# bao1x_peri register map
Vendor: baochip
Registers are 32-bit, read-write, reset 0x0 unless marked. A register's access mark holds for its fields unless they carry their own. Offsets are from the block's base; [hi:lo] are bit positions; {n}, {i} and the like mark numbered series; <NAME> marks a mode.

## PWM
Base 0x50120000
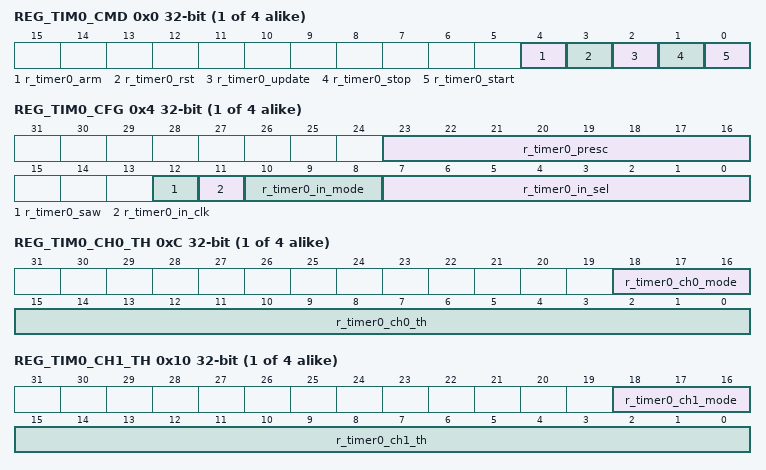
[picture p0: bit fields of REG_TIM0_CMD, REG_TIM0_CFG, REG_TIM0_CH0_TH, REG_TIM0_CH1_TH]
{0x0+0x40*i} REG_TIM{i}_CMD (i=0..3) — See `adv_timer_apb_if.sv <https://github.com/baochip/baochip-1x/blob/main/rtl/ip s/apb/apb_adv_timer/rtl/adv_timer_apb_if.sv>`__
  [4] r_timer{i}_arm, [3] r_timer{i}_rst, [2] r_timer{i}_update, [1] r_timer{i}_stop, [0] r_timer{i}_start
{0x4+0x40*i} REG_TIM{i}_CFG (i=0..3) — See `adv_timer_apb_if.sv <https://github.com/baochip/baochip-1x/blob/main/rtl/ip s/apb/apb_adv_timer/rtl/adv_timer_apb_if.sv>`__
  [23:16] r_timer{i}_presc, [12] r_timer{i}_saw, [11] r_timer{i}_in_clk, [10:8] r_timer{i}_in_mode, [7:0] r_timer{i}_in_sel
{0xC+0x40*i} REG_TIM{i}_CH0_TH (i=0..3) — See `adv_timer_apb_if.sv <https://github.com/baochip/baochip-1x/blob/main/rtl/ip s/apb/apb_adv_timer/rtl/adv_timer_apb_if.sv>`__
  [18:16] r_timer{i}_ch0_mode, [15:0] r_timer{i}_ch0_th
{0x10+0x40*i} REG_TIM{i}_CH1_TH (i=0..3) — See `adv_timer_apb_if.sv <https://github.com/baochip/baochip-1x/blob/main/rtl/ip s/apb/apb_adv_timer/rtl/adv_timer_apb_if.sv>`__
  [18:16] r_timer{i}_ch1_mode, [15:0] r_timer{i}_ch1_th
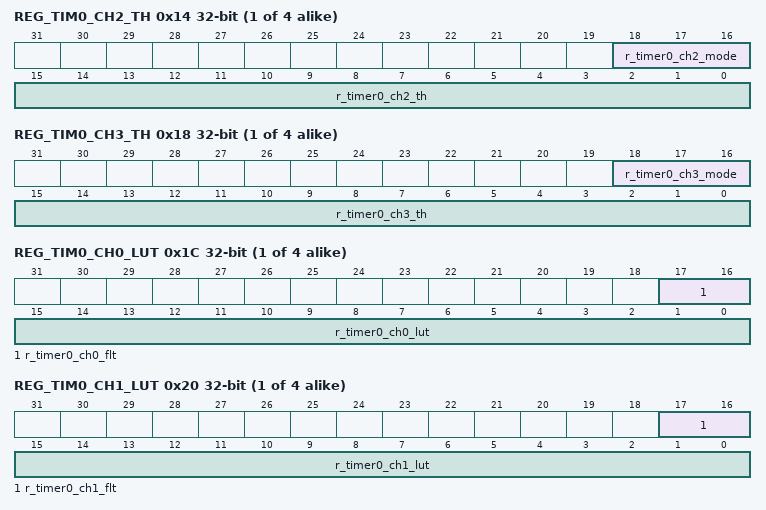
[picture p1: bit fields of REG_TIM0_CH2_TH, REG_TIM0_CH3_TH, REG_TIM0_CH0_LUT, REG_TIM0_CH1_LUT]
{0x14+0x40*i} REG_TIM{i}_CH2_TH (i=0..3) — See `adv_timer_apb_if.sv <https://github.com/baochip/baochip-1x/blob/main/rtl/ip s/apb/apb_adv_timer/rtl/adv_timer_apb_if.sv>`__
  [18:16] r_timer{i}_ch2_mode, [15:0] r_timer{i}_ch2_th
{0x18+0x40*i} REG_TIM{i}_CH3_TH (i=0..3) — See `adv_timer_apb_if.sv <https://github.com/baochip/baochip-1x/blob/main/rtl/ip s/apb/apb_adv_timer/rtl/adv_timer_apb_if.sv>`__
  [18:16] r_timer{i}_ch3_mode, [15:0] r_timer{i}_ch3_th
{0x1C+0x40*i} REG_TIM{i}_CH0_LUT (i=0..3) — See `adv_timer_apb_if.sv <https://github.com/baochip/baochip-1x/blob/main/rtl/ip s/apb/apb_adv_timer/rtl/adv_timer_apb_if.sv>`__
  [17:16] r_timer{i}_ch0_flt, [15:0] r_timer{i}_ch0_lut
{0x20+0x40*i} REG_TIM{i}_CH1_LUT (i=0..3) — See `adv_timer_apb_if.sv <https://github.com/baochip/baochip-1x/blob/main/rtl/ip s/apb/apb_adv_timer/rtl/adv_timer_apb_if.sv>`__
  [17:16] r_timer{i}_ch1_flt, [15:0] r_timer{i}_ch1_lut
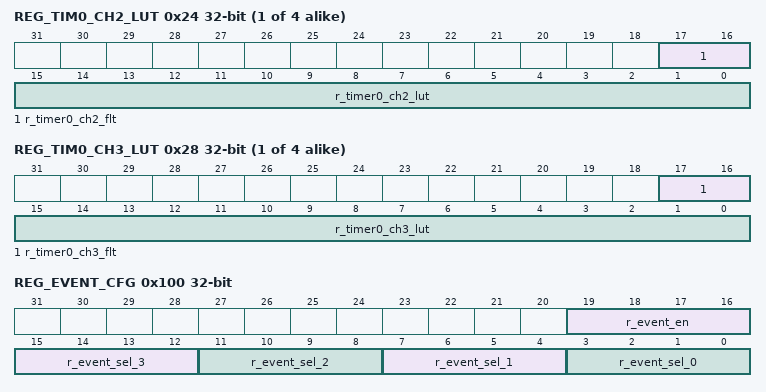
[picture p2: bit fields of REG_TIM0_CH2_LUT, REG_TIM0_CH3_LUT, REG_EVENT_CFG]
{0x24+0x40*i} REG_TIM{i}_CH2_LUT (i=0..3) — See `adv_timer_apb_if.sv <https://github.com/baochip/baochip-1x/blob/main/rtl/ip s/apb/apb_adv_timer/rtl/adv_timer_apb_if.sv>`__
  [17:16] r_timer{i}_ch2_flt, [15:0] r_timer{i}_ch2_lut
{0x28+0x40*i} REG_TIM{i}_CH3_LUT (i=0..3) — See `adv_timer_apb_if.sv <https://github.com/baochip/baochip-1x/blob/main/rtl/ip s/apb/apb_adv_timer/rtl/adv_timer_apb_if.sv>`__
  [17:16] r_timer{i}_ch3_flt, [15:0] r_timer{i}_ch3_lut
0x100 REG_EVENT_CFG — See `adv_timer_apb_if.sv <https://github.com/baochip/baochip-1x/blob/main/rtl/ip s/apb/apb_adv_timer/rtl/adv_timer_apb_if.sv>`__
  [19:16] r_event_en, [4n+3:4n] r_event_sel_{n} (n=0..3)
0x104 REG_CH_EN — See `adv_timer_apb_if.sv <https://github.com/baochip/baochip-1x/blob/main/rtl/ip s/apb/apb_adv_timer/rtl/adv_timer_apb_if.sv>`__
  [3:0] r_clk_en
{0x140+4i} REG_PREFD{i} (i=0..3) — See `adv_timer_apb_if.sv <https://github.com/baochip/baochip-1x/blob/main/rtl/ip s/apb/apb_adv_timer/rtl/adv_timer_apb_if.sv>`__
  [9:0] lsclk_prefd_{i}

## CORESUB_SRAMTRM
Base 0x40014000
0x00 SFR_CACHE — See `coresub_sramtrm.sv#L54 <https://github.com/baochip/baochip-1x/blob/main/rtl /modules/core/rtl/coresub_sramtrm.sv#L54>`__ (line numbers are approximate)
  [2:0] sfr_cache — sfr_cache read/write control register
0x04 SFR_ITCM — See `coresub_sramtrm.sv#L55 <https://github.com/baochip/baochip-1x/blob/main/rtl /modules/core/rtl/coresub_sramtrm.sv#L55>`__ (line numbers are approximate)
  [4:0] sfr_itcm — sfr_itcm read/write control register
0x08 SFR_DTCM — See `coresub_sramtrm.sv#L56 <https://github.com/baochip/baochip-1x/blob/main/rtl /modules/core/rtl/coresub_sramtrm.sv#L56>`__ (line numbers are approximate)
  [4:0] sfr_dtcm — sfr_dtcm read/write control register
0x0C SFR_SRAM0 — See `coresub_sramtrm.sv#L57 <https://github.com/baochip/baochip-1x/blob/main/rtl /modules/core/rtl/coresub_sramtrm.sv#L57>`__ (line numbers are approximate)
  [4:0] sfr_sram0 — sfr_sram0 read/write control register
0x10 SFR_SRAM1 — See `coresub_sramtrm.sv#L58 <https://github.com/baochip/baochip-1x/blob/main/rtl /modules/core/rtl/coresub_sramtrm.sv#L58>`__ (line numbers are approximate)
  [4:0] sfr_sram1 — sfr_sram1 read/write control register
0x14 SFR_VEXRAM — See `coresub_sramtrm.sv#L59 <https://github.com/baochip/baochip-1x/blob/main/rtl /modules/core/rtl/coresub_sramtrm.sv#L59>`__ (line numbers are approximate)
  [2:0] sfr_vexram — sfr_vexram read/write control register
0x20 SFR_SRAMERR — See `coresub_sramtrm.sv#L60 <https://github.com/baochip/baochip-1x/blob/main/rtl /modules/core/rtl/coresub_sramtrm.sv#L60>`__ (line numbers are approximate)
  [3:0] srambankerr — srambankerr flag register. `1` means event happened, write back `1` in respective bit position to clear the flag
0x30 SFR_RAMSEC — See `coresub_sramtrm.sv#L61 <https://github.com/baochip/baochip-1x/blob/main/rtl /modules/core/rtl/coresub_sramtrm.sv#L61>`__ (line numbers are approximate)
  [3:0] ramsec — ramsec read/write control register
